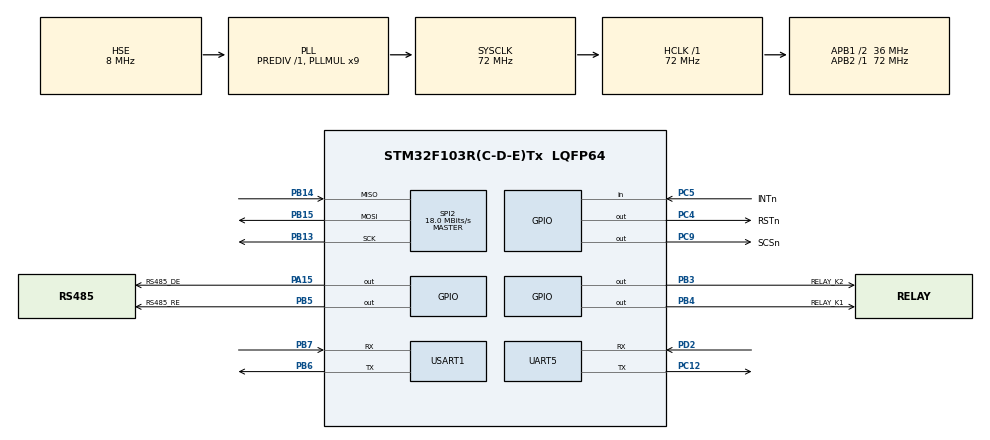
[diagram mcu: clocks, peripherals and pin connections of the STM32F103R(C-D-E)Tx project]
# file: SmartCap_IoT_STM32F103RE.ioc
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FREERTOS.INCLUDE_vTaskDelayUntil=1
FREERTOS.Queues01=Queue_RS485_To_RG200U,256,1,1,Dynamic,NULL,NULL;Queue_RG200U_To_RS485,256,1,1,Dynamic,NULL,NULL
FREERTOS.Tasks01=defaultTask,-2,128,StartDefaultTask,As weak,NULL,Dynamic,NULL,NULL;RS485_RxTask,1,512,Task_RS485_Handler,As weak,NULL,Dynamic,NULL,NULL;RG200U_RxTask,1,512,Task_RG200U_Handler,As weak,NULL,Dynamic,NULL,NULL;RS485_TxTask,0,512,Task_RS485_Transmit,As weak,NULL,Dynamic,NULL,NULL;RG200U_TxTask,0,512,Task_RG200U_Transmit,As weak,NULL,Dynamic,NULL,NULL
FREERTOS.configMAX_PRIORITIES=5
FREERTOS.configTOTAL_HEAP_SIZE=10240
Mcu.Family=STM32F1
Mcu.Name=STM32F103R(C-D-E)Tx
Mcu.Package=LQFP64
NVIC.PriorityGroup=NVIC_PRIORITYGROUP_4
NVIC.TIM1_UP_IRQn=true\:15\:0\:false\:false\:true\:false\:false\:true\:true
NVIC.TIM2_IRQn=true\:5\:0\:false\:false\:true\:true\:true\:true\:true
NVIC.TimeBase=TIM1_UP_IRQn
NVIC.TimeBaseIP=TIM1
NVIC.UART5_IRQn=true\:5\:0\:false\:false\:true\:true\:true\:true\:true
NVIC.USART1_IRQn=true\:5\:0\:false\:false\:true\:true\:true\:true\:true
PA13.Mode=Serial_Wire
PA13.Signal=SYS_JTMS-SWDIO
PA14.Mode=Serial_Wire
PA14.Signal=SYS_JTCK-SWCLK
PA15.GPIO_Label=RS485_DE
PA15.Signal=GPIO_Output
PB13.Mode=Full_Duplex_Master
PB13.Signal=SPI2_SCK
PB14.Mode=Full_Duplex_Master
PB14.Signal=SPI2_MISO
PB15.Mode=Full_Duplex_Master
PB15.Signal=SPI2_MOSI
PB3.GPIO_Label=RELAY_K2
PB3.Signal=GPIO_Output
PB4.GPIO_Label=RELAY_K1
PB4.Signal=GPIO_Output
PB5.GPIO_Label=RS485_RE
PB5.PinState=GPIO_PIN_SET
PB5.Signal=GPIO_Output
PB6.Mode=Asynchronous
PB6.Signal=USART1_TX
PB7.Mode=Asynchronous
PB7.Signal=USART1_RX
PC12.Mode=Asynchronous
PC12.Signal=UART5_TX
PC14-OSC32_IN.Mode=LSE-External-Oscillator
PC14-OSC32_IN.Signal=RCC_OSC32_IN
PC15-OSC32_OUT.Mode=LSE-External-Oscillator
PC15-OSC32_OUT.Signal=RCC_OSC32_OUT
PC4.GPIO_Label=RSTn
PC4.GPIO_ModeDefaultOutputPP=GPIO_MODE_OUTPUT_OD
PC4.GPIO_PuPd=GPIO_PULLUP
PC4.GPIO_Speed=GPIO_SPEED_FREQ_HIGH
PC4.PinState=GPIO_PIN_SET
PC4.Signal=GPIO_Output
PC5.GPIO_Label=INTn
PC5.GPIO_Mode=GPIO_MODE_INPUT
PC5.GPIO_PuPd=GPIO_NOPULL
PC5.Signal=GPIO_Input
PC9.GPIO_Label=SCSn
PC9.GPIO_ModeDefaultOutputPP=GPIO_MODE_OUTPUT_OD
PC9.GPIO_PuPd=GPIO_PULLUP
PC9.GPIO_Speed=GPIO_SPEED_FREQ_HIGH
PC9.PinState=GPIO_PIN_SET
PC9.Signal=GPIO_Output
PD0-OSC_IN.Mode=HSE-External-Oscillator
PD0-OSC_IN.Signal=RCC_OSC_IN
PD1-OSC_OUT.Mode=HSE-External-Oscillator
PD1-OSC_OUT.Signal=RCC_OSC_OUT
PD2.Mode=Asynchronous
PD2.Signal=UART5_RX
ProjectManager.HeapSize=0x200
ProjectManager.StackSize=0x400
ProjectManager.TargetToolchain=MDK-ARM V5.32
RCC.AHBFreq_Value=72000000
RCC.APB1CLKDivider=RCC_HCLK_DIV2
RCC.APB1Freq_Value=36000000
RCC.APB1TimFreq_Value=72000000
RCC.APB2Freq_Value=72000000
RCC.APB2TimFreq_Value=72000000
RCC.HCLKFreq_Value=72000000
RCC.PLLMUL=RCC_PLL_MUL9
RCC.PLLSourceVirtual=RCC_PLLSOURCE_HSE
RCC.SYSCLKFreq_VALUE=72000000
RCC.SYSCLKSource=RCC_SYSCLKSOURCE_PLLCLK
RCC.USBFreq_Value=72000000
SPI2.CalculateBaudRate=18.0 MBits/s
SPI2.Direction=SPI_DIRECTION_2LINES
SPI2.Mode=SPI_MODE_MASTER
SPI2.VirtualType=VM_MASTER
TIM2.Period=1000-1
TIM2.Prescaler=72-1
UART5.VirtualMode=Asynchronous
USART1.VirtualMode=VM_ASYNC
VP_FREERTOS_VS_CMSIS_V1.Mode=CMSIS_V1
VP_SYS_VS_tim1.Mode=TIM1
VP_TIM2_VS_ClockSourceINT.Mode=Internal
board=custom

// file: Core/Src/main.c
/* USER CODE BEGIN Header */
/**
  ******************************************************************************
  * @file           : main.c
  * @brief          : Main program body
  ******************************************************************************
  * @attention
  *
  * Copyright (c) 2026 STMicroelectronics.
  * All rights reserved.
  *
  * This software is licensed under terms that can be found in the LICENSE file
  * in the root directory of this software component.
  * If no LICENSE file comes with this software, it is provided AS-IS.
  *
  ******************************************************************************
  */
/* USER CODE END Header */
#include "main.h"
#include "cmsis_os.h"
#include "spi.h"
#include "tim.h"
#include "usart.h"
#include "gpio.h"

/* USER CODE BEGIN Includes */

#include "User_main.h"

/* USER CODE END Includes */

void SystemClock_Config(void);
void MX_FREERTOS_Init(void);

int main(void)
{

  /* MCU Configuration--------------------------------------------------------*/

  /* Reset of all peripherals, Initializes the Flash interface and the Systick. */
  HAL_Init();

  /* Configure the system clock */
  SystemClock_Config();

  /* Initialize all configured peripherals */
  MX_GPIO_Init();
  MX_SPI2_Init();
  MX_TIM2_Init();
  MX_USART1_UART_Init();
  MX_UART5_Init();
  /* USER CODE BEGIN 2 */

  User_main();

  /* USER CODE END 2 */

  /* Call init function for freertos objects (in cmsis_os2.c) */
  MX_FREERTOS_Init();

  /* Start scheduler */
  osKernelStart();

  /* We should never get here as control is now taken by the scheduler */

  /* Infinite loop */
  while (1)
  {

  }
}

void SystemClock_Config(void)
{
  RCC_OscInitTypeDef RCC_OscInitStruct = {0};
  RCC_ClkInitTypeDef RCC_ClkInitStruct = {0};

  /** Initializes the RCC Oscillators according to the specified parameters
  * in the RCC_OscInitTypeDef structure.
  */
  RCC_OscInitStruct.OscillatorType = RCC_OSCILLATORTYPE_HSE;
  RCC_OscInitStruct.HSEState = RCC_HSE_ON;
  RCC_OscInitStruct.HSEPredivValue = RCC_HSE_PREDIV_DIV1;
  RCC_OscInitStruct.HSIState = RCC_HSI_ON;
  RCC_OscInitStruct.PLL.PLLState = RCC_PLL_ON;
  RCC_OscInitStruct.PLL.PLLSource = RCC_PLLSOURCE_HSE;
  RCC_OscInitStruct.PLL.PLLMUL = RCC_PLL_MUL9;
  if (HAL_RCC_OscConfig(&RCC_OscInitStruct) != HAL_OK)
  {
    Error_Handler();
  }

  /** Initializes the CPU, AHB and APB buses clocks
  */
  RCC_ClkInitStruct.ClockType = RCC_CLOCKTYPE_HCLK|RCC_CLOCKTYPE_SYSCLK
                              |RCC_CLOCKTYPE_PCLK1|RCC_CLOCKTYPE_PCLK2;
  RCC_ClkInitStruct.SYSCLKSource = RCC_SYSCLKSOURCE_PLLCLK;
  RCC_ClkInitStruct.AHBCLKDivider = RCC_SYSCLK_DIV1;
  RCC_ClkInitStruct.APB1CLKDivider = RCC_HCLK_DIV2;
  RCC_ClkInitStruct.APB2CLKDivider = RCC_HCLK_DIV1;

  if (HAL_RCC_ClockConfig(&RCC_ClkInitStruct, FLASH_LATENCY_2) != HAL_OK)
  {
    Error_Handler();
  }
}

void HAL_TIM_PeriodElapsedCallback(TIM_HandleTypeDef *htim)
{
  if (htim->Instance == TIM1)
  {
    HAL_IncTick();
  }
  /* USER CODE BEGIN Callback 1 */

  // TIM2: W5500定时器中断处理
  if (htim->Instance == TIM2)
  {
    extern void wiz_timer_handler(void);
    wiz_timer_handler();
  }

  /* USER CODE END Callback 1 */
}

void Error_Handler(void)
{
  __disable_irq();
  while (1)
  {
  }
}

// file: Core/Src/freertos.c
/* USER CODE BEGIN Header */
/**
  ******************************************************************************
  * File Name          : freertos.c
  * Description        : Code for freertos applications
  ******************************************************************************
  * @attention
  *
  * Copyright (c) 2026 STMicroelectronics.
  * All rights reserved.
  *
  * This software is licensed under terms that can be found in the LICENSE file
  * in the root directory of this software component.
  * If no LICENSE file comes with this software, it is provided AS-IS.
  *
  ******************************************************************************
  */
/* USER CODE END Header */

#include "FreeRTOS.h"
#include "task.h"
#include "main.h"
#include "cmsis_os.h"

/* USER CODE BEGIN Includes */

#include "user_tasks.h"  // 用户任务实现

/* USER CODE END Includes */

osThreadId defaultTaskHandle;
osThreadId RS485_RxTaskHandle;
osThreadId RG200U_RxTaskHandle;
osThreadId RS485_TxTaskHandle;
osThreadId RG200U_TxTaskHandle;
osMessageQId Queue_RS485_To_RG200UHandle;
osMessageQId Queue_RG200U_To_RS485Handle;

void StartDefaultTask(void const * argument);
void Task_RS485_Handler(void const * argument);
void Task_RG200U_Handler(void const * argument);
void Task_RS485_Transmit(void const * argument);
void Task_RG200U_Transmit(void const * argument);

void MX_FREERTOS_Init(void); /* (MISRA C 2004 rule 8.1) */

/* GetIdleTaskMemory prototype (linked to static allocation support) */
void vApplicationGetIdleTaskMemory( StaticTask_t **ppxIdleTaskTCBBuffer, StackType_t **ppxIdleTaskStackBuffer, uint32_t *pulIdleTaskStackSize );

/* USER CODE BEGIN GET_IDLE_TASK_MEMORY */
static StaticTask_t xIdleTaskTCBBuffer;
static StackType_t xIdleStack[configMINIMAL_STACK_SIZE];

void vApplicationGetIdleTaskMemory( StaticTask_t **ppxIdleTaskTCBBuffer, StackType_t **ppxIdleTaskStackBuffer, uint32_t *pulIdleTaskStackSize )
{
  *ppxIdleTaskTCBBuffer = &xIdleTaskTCBBuffer;
  *ppxIdleTaskStackBuffer = &xIdleStack[0];
  *pulIdleTaskStackSize = configMINIMAL_STACK_SIZE;
  /* place for user code */
}
/* USER CODE END GET_IDLE_TASK_MEMORY */

void MX_FREERTOS_Init(void) {

  /* Create the queue(s) */
  /* definition and creation of Queue_RS485_To_RG200U */
  osMessageQDef(Queue_RS485_To_RG200U, 256, 1);
  Queue_RS485_To_RG200UHandle = osMessageCreate(osMessageQ(Queue_RS485_To_RG200U), NULL);

  /* definition and creation of Queue_RG200U_To_RS485 */
  osMessageQDef(Queue_RG200U_To_RS485, 256, 1);
  Queue_RG200U_To_RS485Handle = osMessageCreate(osMessageQ(Queue_RG200U_To_RS485), NULL);

  /* Create the thread(s) */
  /* definition and creation of defaultTask */
  osThreadDef(defaultTask, StartDefaultTask, osPriorityLow, 0, 128);
  defaultTaskHandle = osThreadCreate(osThread(defaultTask), NULL);

  /* definition and creation of RS485_RxTask */
  osThreadDef(RS485_RxTask, Task_RS485_Handler, osPriorityAboveNormal, 0, 512);
  RS485_RxTaskHandle = osThreadCreate(osThread(RS485_RxTask), NULL);

  /* definition and creation of RG200U_RxTask */
  osThreadDef(RG200U_RxTask, Task_RG200U_Handler, osPriorityAboveNormal, 0, 512);
  RG200U_RxTaskHandle = osThreadCreate(osThread(RG200U_RxTask), NULL);

  /* definition and creation of RS485_TxTask */
  osThreadDef(RS485_TxTask, Task_RS485_Transmit, osPriorityNormal, 0, 512);
  RS485_TxTaskHandle = osThreadCreate(osThread(RS485_TxTask), NULL);

  /* definition and creation of RG200U_TxTask */
  osThreadDef(RG200U_TxTask, Task_RG200U_Transmit, osPriorityNormal, 0, 512);
  RG200U_TxTaskHandle = osThreadCreate(osThread(RG200U_TxTask), NULL);

}

__weak void StartDefaultTask(void const * argument)
{
  /* USER CODE BEGIN StartDefaultTask */

  /* 转发到用户任务实现 */
  UserTask_Default(argument);

  /* USER CODE END StartDefaultTask */
}

__weak void Task_RS485_Handler(void const * argument)
{
  /* USER CODE BEGIN Task_RS485_Handler */

  /* 转发到用户任务实现 */
  UserTask_RS485_RxHandler(argument);

  /* USER CODE END Task_RS485_Handler */
}

__weak void Task_RG200U_Handler(void const * argument)
{
  /* USER CODE BEGIN Task_RG200U_Handler */

  /* 转发到用户任务实现 */
  UserTask_RG200U_RxHandler(argument);

  /* USER CODE END Task_RG200U_Handler */
}

__weak void Task_RS485_Transmit(void const * argument)
{
  /* USER CODE BEGIN Task_RS485_Transmit */

  /* 转发到用户任务实现 */
  UserTask_RS485_TxHandler(argument);

  /* USER CODE END Task_RS485_Transmit */
}

__weak void Task_RG200U_Transmit(void const * argument)
{
  /* USER CODE BEGIN Task_RG200U_Transmit */

  /* 转发到用户任务实现 */
  UserTask_RG200U_TxHandler(argument);

  /* USER CODE END Task_RG200U_Transmit */
}
